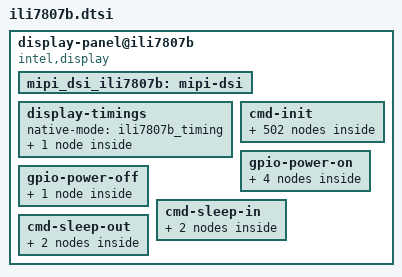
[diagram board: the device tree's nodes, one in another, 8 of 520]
/*
 * definition at "include/dt-bindings/sofiafb/sofia_fb.h"
 */

display-panel@ili7807b{
	compatible = "intel,display";
	intel,display-dc-clkrate = <297000000>;
	intel,display-preinit = <0>;
	intel,display-ramless = <1>;
	intel,display-fps = <30>;
	intel,display-vid-mode = "pulses";
	intel,display-vid-id = <0>;
	intel,display-eot = <1>;
	intel,display-gate = <1>;
	intel,display-if-dts = <1>;
	intel,display-if = <&mipi_dsi_ili7807b>;
	mipi_dsi_ili7807b:mipi-dsi {
		intel,display-if-rate = <400000000>;
		intel,display-if-nblanes = <4>;
		intel,display-if-phy-pwup = <6>;
		intel,display-if-phy-calib = <3>;
		intel,display-if-phy-to_lp_hs_req = <24>;
		intel,display-if-phy-to_lp_hs_dis = <25>;
		intel,display-if-phy-to_lp_hs_eot = <60>;
		intel,display-if-phy-to_hs_zero = <13>;
		intel,display-if-phy-to_hs_flip = <24>;
		intel,display-if-phy-lp_clk_div = <31>;
		intel,display-if-phy-to_hs_clk_pre = <36>;
		intel,display-if-phy-to_hs_clk_post = <42>;
		intel,display-if-phy-data_delay = <7>;
		intel,display-if-phy-clock_delay = <7>;
		intel,display-if-phy-lp_tx_tfall = <2>;
		intel,display-if-phy-lp_tx_rise = <2>;
		intel,display-if-phy-lp_tx_vref = <31>;
	};

	display-timings {
		native-mode = <&ili7807b_timing>;
		ili7807b_timing: ili7807b_timing {
			screen-type = <SCREEN_MIPI>;
			out-face    = <OUT_P888>;
			color-mode = <COLOR_RGB>;
			width = <75>;
			height = <132>;
			clock-frequency = <65774400>;
			hactive = <1080>;
			vactive = <1920>;
			hback-porch = <24>;
			hfront-porch = <24>;
			vback-porch = <4>;
			vfront-porch = <4>;
			hsync-len = <8>;
			vsync-len = <2>;
			hsync-active = <0>;
			vsync-active = <0>;
			de-active = <0>;
			pixelclk-active = <0>;
			swap-rb = <0>;
			swap-rg = <0>;
			swap-gb = <0>;
		};
	};

	cmd-init {
	    ili7807b_cmd0 {
		     intel,cmd-type = <0x39>;
		     intel,cmd-data = <0xFF 0x78 0x07 0x01>;
		     intel,cmd-lp = <1>;
		 };
	    ili7807b_cmd1 {
		     intel,cmd-type = <0x15>;
		     intel,cmd-data = <0x42 0x11>;
		     intel,cmd-lp = <1>;
		 };
	    ili7807b_cmd2 {
		     intel,cmd-type = <0x15>;
		     intel,cmd-data = <0x43 0xB0>;
		     intel,cmd-lp = <1>;
		 };
	    ili7807b_cmd3 {
		     intel,cmd-type = <0x15>;
		     intel,cmd-data = <0x44 0xBA>;
		     intel,cmd-lp = <1>;
		 };
	    ili7807b_cmd4 {
		     intel,cmd-type = <0x15>;
		     intel,cmd-data = <0x45 0x29>;
		     intel,cmd-lp = <1>;
		 };
	    ili7807b_cmd5 {
		     intel,cmd-type = <0x15>;
		     intel,cmd-data = <0x46 0x39>;
		     intel,cmd-lp = <1>;
		 };
	    ili7807b_cmd6 {
		     intel,cmd-type = <0x15>;
		     intel,cmd-data = <0x4A 0x12>;
		     intel,cmd-lp = <1>;
		 };
	    ili7807b_cmd7 {
		     intel,cmd-type = <0x15>;
		     intel,cmd-data = <0x4B 0x12>;
		     intel,cmd-lp = <1>;
		 };
	    ili7807b_cmd8 {
		     intel,cmd-type = <0x15>;
		     intel,cmd-data = <0x50 0x3F>;
		     intel,cmd-lp = <1>;
		 };
	    ili7807b_cmd9 {
		     intel,cmd-type = <0x15>;
		     intel,cmd-data = <0x51 0x3F>;
		     intel,cmd-lp = <1>;
		 };
	    ili7807b_cmd10 {
		     intel,cmd-type = <0x15>;
		     intel,cmd-data = <0xA2 0x01>;
		     intel,cmd-lp = <1>;
		 };
	    ili7807b_cmd11 {
		     intel,cmd-type = <0x15>;
		     intel,cmd-data = <0xA3 0x1F>;
		     intel,cmd-lp = <1>;
		 };
	    ili7807b_cmd12 {
		     intel,cmd-type = <0x15>;
		     intel,cmd-data = <0xA4 0x01>;
		     intel,cmd-lp = <1>;
		 };
	    ili7807b_cmd13 {
		     intel,cmd-type = <0x15>;
		     intel,cmd-data = <0xA5 0x19>;
		     intel,cmd-lp = <1>;
		 };
	    ili7807b_cmd14 {
		     intel,cmd-type = <0x39>;
		     intel,cmd-data = <0xFF 0x78 0x07 0x01>;
		     intel,cmd-lp = <1>;
		 };
	    ili7807b_cmd15 {
		     intel,cmd-type = <0x15>;
		     intel,cmd-data = <0x22 0x06>;
		     intel,cmd-lp = <1>;
		 };
	    ili7807b_cmd16 {
		     intel,cmd-type = <0x15>;
		     intel,cmd-data = <0x36 0x01>;
		     intel,cmd-lp = <1>;
		 };
	    ili7807b_cmd17 {
		     intel,cmd-type = <0x15>;
		     intel,cmd-data = <0x64 0x10>;
		     intel,cmd-lp = <1>;
		 };
	    ili7807b_cmd18 {
		     intel,cmd-type = <0x15>;
		     intel,cmd-data = <0x6C 0x45>;
		     intel,cmd-lp = <1>;
		 };
	    ili7807b_cmd19 {
		     intel,cmd-type = <0x15>;
		     intel,cmd-data = <0x6D 0x17>;
		     intel,cmd-lp = <1>;
		 };
	    ili7807b_cmd20 {
		     intel,cmd-type = <0x39>;
		     intel,cmd-data = <0xFF 0x78 0x07 0x06>;
		     intel,cmd-lp = <1>;
		 };
	    ili7807b_cmd21 {
		     intel,cmd-type = <0x15>;
		     intel,cmd-data = <0x00 0x41>;
		     intel,cmd-lp = <1>;
		 };
	    ili7807b_cmd22 {
		     intel,cmd-type = <0x15>;
		     intel,cmd-data = <0x01 0x01>;
		     intel,cmd-lp = <1>;
		 };
	    ili7807b_cmd23 {
		     intel,cmd-type = <0x15>;
		     intel,cmd-data = <0x02 0x22>;
		     intel,cmd-lp = <1>;
		 };
	    ili7807b_cmd24 {
		     intel,cmd-type = <0x15>;
		     intel,cmd-data = <0x03 0x22>;
		     intel,cmd-lp = <1>;
		 };
	    ili7807b_cmd25 {
		     intel,cmd-type = <0x15>;
		     intel,cmd-data = <0x04 0x02>;
		     intel,cmd-lp = <1>;
		 };
	    ili7807b_cmd26 {
		     intel,cmd-type = <0x15>;
		     intel,cmd-data = <0x05 0x00>;
		     intel,cmd-lp = <1>;
		 };
	    ili7807b_cmd27 {
		     intel,cmd-type = <0x15>;
		     intel,cmd-data = <0x06 0x04>;
		     intel,cmd-lp = <1>;
		 };
	    ili7807b_cmd28 {
		     intel,cmd-type = <0x15>;
		     intel,cmd-data = <0x07 0x00>;
		     intel,cmd-lp = <1>;
		 };
	    ili7807b_cmd29 {
		     intel,cmd-type = <0x15>;
		     intel,cmd-data = <0x08 0x00>;
		     intel,cmd-lp = <1>;
		 };
	    ili7807b_cmd30 {
		     intel,cmd-type = <0x15>;
		     intel,cmd-data = <0x09 0x00>;
		     intel,cmd-lp = <1>;
		 };
	    ili7807b_cmd31 {
		     intel,cmd-type = <0x15>;
		     intel,cmd-data = <0x0A 0x10>;
		     intel,cmd-lp = <1>;
		 };
	    ili7807b_cmd32 {
		     intel,cmd-type = <0x15>;
		     intel,cmd-data = <0x0B 0x30>;
		     intel,cmd-lp = <1>;
		 };
	    ili7807b_cmd33 {
		     intel,cmd-type = <0x15>;
		     intel,cmd-data = <0x0C 0x04>;
		     intel,cmd-lp = <1>;
		 };
	    ili7807b_cmd34 {
		     intel,cmd-type = <0x15>;
		     intel,cmd-data = <0x0D 0x04>;
		     intel,cmd-lp = <1>;
		 };
	    ili7807b_cmd35 {
		     intel,cmd-type = <0x15>;
		     intel,cmd-data = <0x0E 0x00>;
		     intel,cmd-lp = <1>;
		 };
	    ili7807b_cmd36 {
		     intel,cmd-type = <0x15>;
		     intel,cmd-data = <0x0F 0x00>;
		     intel,cmd-lp = <1>;
		 };
	    ili7807b_cmd37 {
		     intel,cmd-type = <0x15>;
		     intel,cmd-data = <0x10 0x00>;
		     intel,cmd-lp = <1>;
		 };
	    ili7807b_cmd38 {
		     intel,cmd-type = <0x15>;
		     intel,cmd-data = <0x11 0x00>;
		     intel,cmd-lp = <1>;
		 };
	    ili7807b_cmd39 {
		     intel,cmd-type = <0x15>;
		     intel,cmd-data = <0x12 0x00>;
		     intel,cmd-lp = <1>;
		 };
	    ili7807b_cmd40 {
		     intel,cmd-type = <0x15>;
		     intel,cmd-data = <0x13 0x00>;
		     intel,cmd-lp = <1>;
		 };
	    ili7807b_cmd41 {
		     intel,cmd-type = <0x15>;
		     intel,cmd-data = <0x14 0x00>;
		     intel,cmd-lp = <1>;
		 };
	    ili7807b_cmd42 {
		     intel,cmd-type = <0x15>;
		     intel,cmd-data = <0x15 0x00>;
		     intel,cmd-lp = <1>;
		 };
	    ili7807b_cmd43 {
		     intel,cmd-type = <0x15>;
		     intel,cmd-data = <0x31 0x08>;
		     intel,cmd-lp = <1>;
		 };
	    ili7807b_cmd44 {
		     intel,cmd-type = <0x15>;
		     intel,cmd-data = <0x32 0x01>;
		     intel,cmd-lp = <1>;
		 };
	    ili7807b_cmd45 {
		     intel,cmd-type = <0x15>;
		     intel,cmd-data = <0x33 0x00>;
		     intel,cmd-lp = <1>;
		 };
	    ili7807b_cmd46 {
		     intel,cmd-type = <0x15>;
		     intel,cmd-data = <0x34 0x11>;
		     intel,cmd-lp = <1>;
		 };
	    ili7807b_cmd47 {
		     intel,cmd-type = <0x15>;
		     intel,cmd-data = <0x35 0x10>;
		     intel,cmd-lp = <1>;
		 };
	    ili7807b_cmd48 {
		     intel,cmd-type = <0x15>;
		     intel,cmd-data = <0x36 0x26>;
		     intel,cmd-lp = <1>;
		 };
	    ili7807b_cmd49 {
		     intel,cmd-type = <0x15>;
		     intel,cmd-data = <0x37 0x22>;
		     intel,cmd-lp = <1>;
		 };
	    ili7807b_cmd50 {
		     intel,cmd-type = <0x15>;
		     intel,cmd-data = <0x38 0x22>;
		     intel,cmd-lp = <1>;
		 };
	    ili7807b_cmd51 {
		     intel,cmd-type = <0x15>;
		     intel,cmd-data = <0x39 0x0C>;
		     intel,cmd-lp = <1>;
		 };
	    ili7807b_cmd52 {
		     intel,cmd-type = <0x15>;
		     intel,cmd-data = <0x3A 0x02>;
		     intel,cmd-lp = <1>;
		 };
	    ili7807b_cmd53 {
		     intel,cmd-type = <0x15>;
		     intel,cmd-data = <0x3B 0x02>;
		     intel,cmd-lp = <1>;
		 };
	    ili7807b_cmd54 {
		     intel,cmd-type = <0x15>;
		     intel,cmd-data = <0x3C 0x02>;
		     intel,cmd-lp = <1>;
		 };
	    ili7807b_cmd55 {
		     intel,cmd-type = <0x15>;
		     intel,cmd-data = <0x3D 0x02>;
		     intel,cmd-lp = <1>;
		 };
	    ili7807b_cmd56 {
		     intel,cmd-type = <0x15>;
		     intel,cmd-data = <0x3E 0x28>;
		     intel,cmd-lp = <1>;
		 };
	    ili7807b_cmd57 {
		     intel,cmd-type = <0x15>;
		     intel,cmd-data = <0x3F 0x29>;
		     intel,cmd-lp = <1>;
		 };
	    ili7807b_cmd58 {
		     intel,cmd-type = <0x15>;
		     intel,cmd-data = <0x40 0x2A>;
		     intel,cmd-lp = <1>;
		 };
	    ili7807b_cmd59 {
		     intel,cmd-type = <0x15>;
		     intel,cmd-data = <0x41 0x08>;
		     intel,cmd-lp = <1>;
		 };
	    ili7807b_cmd60 {
		     intel,cmd-type = <0x15>;
		     intel,cmd-data = <0x42 0x01>;
		     intel,cmd-lp = <1>;
		 };
	    ili7807b_cmd61 {
		     intel,cmd-type = <0x15>;
		     intel,cmd-data = <0x43 0x00>;
		     intel,cmd-lp = <1>;
		 };
	    ili7807b_cmd62 {
		     intel,cmd-type = <0x15>;
		     intel,cmd-data = <0x44 0x11>;
		     intel,cmd-lp = <1>;
		 };
	    ili7807b_cmd63 {
		     intel,cmd-type = <0x15>;
		     intel,cmd-data = <0x45 0x10>;
		     intel,cmd-lp = <1>;
		 };
	    ili7807b_cmd64 {
		     intel,cmd-type = <0x15>;
		     intel,cmd-data = <0x46 0x26>;
		     intel,cmd-lp = <1>;
		 };
	    ili7807b_cmd65 {
		     intel,cmd-type = <0x15>;
		     intel,cmd-data = <0x47 0x22>;
		     intel,cmd-lp = <1>;
		 };
	    ili7807b_cmd66 {
		     intel,cmd-type = <0x15>;
		     intel,cmd-data = <0x48 0x02>;
		     intel,cmd-lp = <1>;
		 };
	    ili7807b_cmd67 {
		     intel,cmd-type = <0x15>;
		     intel,cmd-data = <0x49 0x0C>;
		     intel,cmd-lp = <1>;
		 };
	    ili7807b_cmd68 {
		     intel,cmd-type = <0x15>;
		     intel,cmd-data = <0x4A 0x02>;
		     intel,cmd-lp = <1>;
		 };
	    ili7807b_cmd69 {
		     intel,cmd-type = <0x15>;
		     intel,cmd-data = <0x4B 0x02>;
		     intel,cmd-lp = <1>;
		 };
	    ili7807b_cmd70 {
		     intel,cmd-type = <0x15>;
		     intel,cmd-data = <0x4C 0x02>;
		     intel,cmd-lp = <1>;
		 };
	    ili7807b_cmd71 {
		     intel,cmd-type = <0x15>;
		     intel,cmd-data = <0x4D 0x02>;
		     intel,cmd-lp = <1>;
		 };
	    ili7807b_cmd72 {
		     intel,cmd-type = <0x15>;
		     intel,cmd-data = <0x4E 0x28>;
		     intel,cmd-lp = <1>;
		 };
	    ili7807b_cmd73 {
		     intel,cmd-type = <0x15>;
		     intel,cmd-data = <0x4F 0x29>;
		     intel,cmd-lp = <1>;
		 };
	    ili7807b_cmd74 {
		     intel,cmd-type = <0x15>;
		     intel,cmd-data = <0x50 0x2A>;
		     intel,cmd-lp = <1>;
		 };
	    ili7807b_cmd75 {
		     intel,cmd-type = <0x15>;
		     intel,cmd-data = <0x61 0x0C>;
		     intel,cmd-lp = <1>;
		 };
	    ili7807b_cmd76 {
		     intel,cmd-type = <0x15>;
		     intel,cmd-data = <0x62 0x01>;
		     intel,cmd-lp = <1>;
		 };
	    ili7807b_cmd77 {
		     intel,cmd-type = <0x15>;
		     intel,cmd-data = <0x63 0x00>;
		     intel,cmd-lp = <1>;
		 };
	    ili7807b_cmd78 {
		     intel,cmd-type = <0x15>;
		     intel,cmd-data = <0x64 0x10>;
		     intel,cmd-lp = <1>;
		 };
	    ili7807b_cmd79 {
		     intel,cmd-type = <0x15>;
		     intel,cmd-data = <0x65 0x11>;
		     intel,cmd-lp = <1>;
		 };
	    ili7807b_cmd80 {
		     intel,cmd-type = <0x15>;
		     intel,cmd-data = <0x66 0x26>;
		     intel,cmd-lp = <1>;
		 };
	    ili7807b_cmd81 {
		     intel,cmd-type = <0x15>;
		     intel,cmd-data = <0x67 0x22>;
		     intel,cmd-lp = <1>;
		 };
	    ili7807b_cmd82 {
		     intel,cmd-type = <0x15>;
		     intel,cmd-data = <0x68 0x22>;
		     intel,cmd-lp = <1>;
		 };
	    ili7807b_cmd83 {
		     intel,cmd-type = <0x15>;
		     intel,cmd-data = <0x69 0x08>;
		     intel,cmd-lp = <1>;
		 };
	    ili7807b_cmd84 {
		     intel,cmd-type = <0x15>;
		     intel,cmd-data = <0x6A 0x02>;
		     intel,cmd-lp = <1>;
		 };
	    ili7807b_cmd85 {
		     intel,cmd-type = <0x15>;
		     intel,cmd-data = <0x6B 0x02>;
		     intel,cmd-lp = <1>;
		 };
	    ili7807b_cmd86 {
		     intel,cmd-type = <0x15>;
		     intel,cmd-data = <0x6C 0x02>;
		     intel,cmd-lp = <1>;
		 };
	    ili7807b_cmd87 {
		     intel,cmd-type = <0x15>;
		     intel,cmd-data = <0x6D 0x02>;
		     intel,cmd-lp = <1>;
		 };
	    ili7807b_cmd88 {
		     intel,cmd-type = <0x15>;
		     intel,cmd-data = <0x6E 0x28>;
		     intel,cmd-lp = <1>;
		 };
	    ili7807b_cmd89 {
		     intel,cmd-type = <0x15>;
		     intel,cmd-data = <0x6F 0x29>;
		     intel,cmd-lp = <1>;
		 };
	    ili7807b_cmd90 {
		     intel,cmd-type = <0x15>;
		     intel,cmd-data = <0x70 0x2A>;
		     intel,cmd-lp = <1>;
		 };
	    ili7807b_cmd91 {
		     intel,cmd-type = <0x15>;
		     intel,cmd-data = <0x71 0x0C>;
		     intel,cmd-lp = <1>;
		 };
	    ili7807b_cmd92 {
		     intel,cmd-type = <0x15>;
		     intel,cmd-data = <0x72 0x01>;
		     intel,cmd-lp = <1>;
		 };
	    ili7807b_cmd93 {
		     intel,cmd-type = <0x15>;
		     intel,cmd-data = <0x73 0x00>;
		     intel,cmd-lp = <1>;
		 };
	    ili7807b_cmd94 {
		     intel,cmd-type = <0x15>;
		     intel,cmd-data = <0x74 0x10>;
		     intel,cmd-lp = <1>;
		 };
	    ili7807b_cmd95 {
		     intel,cmd-type = <0x15>;
		     intel,cmd-data = <0x75 0x11>;
		     intel,cmd-lp = <1>;
		 };
	    ili7807b_cmd96 {
		     intel,cmd-type = <0x15>;
		     intel,cmd-data = <0x76 0x26>;
		     intel,cmd-lp = <1>;
		 };
	    ili7807b_cmd97 {
		     intel,cmd-type = <0x15>;
		     intel,cmd-data = <0x77 0x22>;
		     intel,cmd-lp = <1>;
		 };
	    ili7807b_cmd98 {
		     intel,cmd-type = <0x15>;
		     intel,cmd-data = <0x78 0x02>;
		     intel,cmd-lp = <1>;
		 };
	    ili7807b_cmd99 {
		     intel,cmd-type = <0x15>;
		     intel,cmd-data = <0x79 0x08>;
		     intel,cmd-lp = <1>;
		 };
	    ili7807b_cmd100 {
		     intel,cmd-type = <0x15>;
		     intel,cmd-data = <0x7A 0x02>;
		     intel,cmd-lp = <1>;
		 };
	    ili7807b_cmd101 {
		     intel,cmd-type = <0x15>;
		     intel,cmd-data = <0x7B 0x02>;
		     intel,cmd-lp = <1>;
		 };
	    ili7807b_cmd102 {
		     intel,cmd-type = <0x15>;
		     intel,cmd-data = <0x7C 0x02>;
		     intel,cmd-lp = <1>;
		 };
	    ili7807b_cmd103 {
		     intel,cmd-type = <0x15>;
		     intel,cmd-data = <0x7D 0x02>;
		     intel,cmd-lp = <1>;
		 };
	    ili7807b_cmd104 {
		     intel,cmd-type = <0x15>;
		     intel,cmd-data = <0x7E 0x28>;
		     intel,cmd-lp = <1>;
		 };
	    ili7807b_cmd105 {
		     intel,cmd-type = <0x15>;
		     intel,cmd-data = <0x7F 0x29>;
		     intel,cmd-lp = <1>;
		 };
	    ili7807b_cmd106 {
		     intel,cmd-type = <0x15>;
		     intel,cmd-data = <0x80 0x2A>;
		     intel,cmd-lp = <1>;
		 };
	    ili7807b_cmd107 {
		     intel,cmd-type = <0x15>;
		     intel,cmd-data = <0xD0 0x01>;
		     intel,cmd-lp = <1>;
		 };
	    ili7807b_cmd108 {
		     intel,cmd-type = <0x15>;
		     intel,cmd-data = <0xD1 0x01>;
		     intel,cmd-lp = <1>;
		 };
	    ili7807b_cmd109 {
		     intel,cmd-type = <0x15>;
		     intel,cmd-data = <0xD2 0x10>;
		     intel,cmd-lp = <1>;
		 };
	    ili7807b_cmd110 {
		     intel,cmd-type = <0x15>;
		     intel,cmd-data = <0xD3 0x00>;
		     intel,cmd-lp = <1>;
		 };
	    ili7807b_cmd111 {
		     intel,cmd-type = <0x15>;
		     intel,cmd-data = <0xD4 0x00>;
		     intel,cmd-lp = <1>;
		 };
	    ili7807b_cmd112 {
		     intel,cmd-type = <0x15>;
		     intel,cmd-data = <0xD5 0x00>;
		     intel,cmd-lp = <1>;
		 };
	    ili7807b_cmd113 {
		     intel,cmd-type = <0x15>;
		     intel,cmd-data = <0xD6 0x00>;
		     intel,cmd-lp = <1>;
		 };
	    ili7807b_cmd114 {
		     intel,cmd-type = <0x15>;
		     intel,cmd-data = <0xD7 0x00>;
		     intel,cmd-lp = <1>;
		 };
	    ili7807b_cmd115 {
		     intel,cmd-type = <0x15>;
		     intel,cmd-data = <0xD8 0x00>;
		     intel,cmd-lp = <1>;
		 };
	    ili7807b_cmd116 {
		     intel,cmd-type = <0x15>;
		     intel,cmd-data = <0xD9 0x00>;
		     intel,cmd-lp = <1>;
		 };
	    ili7807b_cmd117 {
		     intel,cmd-type = <0x15>;
		     intel,cmd-data = <0xDA 0x00>;
		     intel,cmd-lp = <1>;
		 };
	    ili7807b_cmd118 {
		     intel,cmd-type = <0x15>;
		     intel,cmd-data = <0xDB 0x47>;
		     intel,cmd-lp = <1>;
		 };
	    ili7807b_cmd119 {
		     intel,cmd-type = <0x15>;
		     intel,cmd-data = <0xDC 0x06>;
		     intel,cmd-lp = <1>;
		 };
	    ili7807b_cmd120 {
		     intel,cmd-type = <0x15>;
		     intel,cmd-data = <0xDD 0x55>;
		     intel,cmd-lp = <1>;
		 };
	    ili7807b_cmd121 {
		     intel,cmd-type = <0x15>;
		     intel,cmd-data = <0x96 0x00>;
		     intel,cmd-lp = <1>;
		 };
	    ili7807b_cmd122 {
		     intel,cmd-type = <0x15>;
		     intel,cmd-data = <0x97 0x12>;
		     intel,cmd-lp = <1>;
		 };
	    ili7807b_cmd123 {
		     intel,cmd-type = <0x15>;
		     intel,cmd-data = <0xA0 0x08>;
		     intel,cmd-lp = <1>;
		 };
	    ili7807b_cmd124 {
		     intel,cmd-type = <0x15>;
		     intel,cmd-data = <0xA1 0x00>;
		     intel,cmd-lp = <1>;
		 };
	    ili7807b_cmd125 {
		     intel,cmd-type = <0x15>;
		     intel,cmd-data = <0xA2 0x04>;
		     intel,cmd-lp = <1>;
		 };
	    ili7807b_cmd126 {
		     intel,cmd-type = <0x15>;
		     intel,cmd-data = <0xA3 0x0F>;
		     intel,cmd-lp = <1>;
		 };
	    ili7807b_cmd127 {
		     intel,cmd-type = <0x15>;
		     intel,cmd-data = <0xA7 0x00>;
		     intel,cmd-lp = <1>;
		 };
	    ili7807b_cmd128 {
		     intel,cmd-type = <0x15>;
		     intel,cmd-data = <0xE5 0x80>;
		     intel,cmd-lp = <1>;
		 };
	    ili7807b_cmd129 {
		     intel,cmd-type = <0x39>;
		     intel,cmd-data = <0xFF 0x78 0x07 0x02>;
		     intel,cmd-lp = <1>;
		 };
	    ili7807b_cmd130 {
		     intel,cmd-type = <0x15>;
		     intel,cmd-data = <0x00 0x00>;
		     intel,cmd-lp = <1>;
		 };
	    ili7807b_cmd131 {
		     intel,cmd-type = <0x15>;
		     intel,cmd-data = <0x01 0x00>;
		     intel,cmd-lp = <1>;
		 };
	    ili7807b_cmd132 {
		     intel,cmd-type = <0x15>;
		     intel,cmd-data = <0x02 0x00>;
		     intel,cmd-lp = <1>;
		 };
	    ili7807b_cmd133 {
		     intel,cmd-type = <0x15>;
		     intel,cmd-data = <0x03 0x19>;
		     intel,cmd-lp = <1>;
		 };
	    ili7807b_cmd134 {
		     intel,cmd-type = <0x15>;
		     intel,cmd-data = <0x04 0x00>;
		     intel,cmd-lp = <1>;
		 };
	    ili7807b_cmd135 {
		     intel,cmd-type = <0x15>;
		     intel,cmd-data = <0x05 0x48>;
		     intel,cmd-lp = <1>;
		 };
	    ili7807b_cmd136 {
		     intel,cmd-type = <0x15>;
		     intel,cmd-data = <0x06 0x00>;
		     intel,cmd-lp = <1>;
		 };
	    ili7807b_cmd137 {
		     intel,cmd-type = <0x15>;
		     intel,cmd-data = <0x07 0x66>;
		     intel,cmd-lp = <1>;
		 };
	    ili7807b_cmd138 {
		     intel,cmd-type = <0x15>;
		     intel,cmd-data = <0x08 0x00>;
		     intel,cmd-lp = <1>;
		 };
	    ili7807b_cmd139 {
		     intel,cmd-type = <0x15>;
		     intel,cmd-data = <0x09 0x7F>;
		     intel,cmd-lp = <1>;
		 };
	    ili7807b_cmd140 {
		     intel,cmd-type = <0x15>;
		     intel,cmd-data = <0x0A 0x00>;
		     intel,cmd-lp = <1>;
		 };
	    ili7807b_cmd141 {
		     intel,cmd-type = <0x15>;
		     intel,cmd-data = <0x0B 0x94>;
		     intel,cmd-lp = <1>;
		 };
	    ili7807b_cmd142 {
		     intel,cmd-type = <0x15>;
		     intel,cmd-data = <0x0C 0x00>;
		     intel,cmd-lp = <1>;
		 };
	    ili7807b_cmd143 {
		     intel,cmd-type = <0x15>;
		     intel,cmd-data = <0x0D 0xA6>;
		     intel,cmd-lp = <1>;
		 };
	    ili7807b_cmd144 {
		     intel,cmd-type = <0x15>;
		     intel,cmd-data = <0x0E 0x00>;
		     intel,cmd-lp = <1>;
		 };
	    ili7807b_cmd145 {
		     intel,cmd-type = <0x15>;
		     intel,cmd-data = <0x0F 0xB5>;
		     intel,cmd-lp = <1>;
		 };
	    ili7807b_cmd146 {
		     intel,cmd-type = <0x15>;
		     intel,cmd-data = <0x10 0x00>;
		     intel,cmd-lp = <1>;
		 };
	    ili7807b_cmd147 {
		     intel,cmd-type = <0x15>;
		     intel,cmd-data = <0x11 0xC4>;
		     intel,cmd-lp = <1>;
		 };
	    ili7807b_cmd148 {
		     intel,cmd-type = <0x15>;
		     intel,cmd-data = <0x12 0x00>;
		     intel,cmd-lp = <1>;
		 };
	    ili7807b_cmd149 {
		     intel,cmd-type = <0x15>;
		     intel,cmd-data = <0x13 0xF6>;
		     intel,cmd-lp = <1>;
		 };
	    ili7807b_cmd150 {
		     intel,cmd-type = <0x15>;
		     intel,cmd-data = <0x14 0x01>;
		     intel,cmd-lp = <1>;
		 };
	    ili7807b_cmd151 {
		     intel,cmd-type = <0x15>;
		     intel,cmd-data = <0x15 0x1E>;
		     intel,cmd-lp = <1>;
		 };
	    ili7807b_cmd152 {
		     intel,cmd-type = <0x15>;
		     intel,cmd-data = <0x16 0x01>;
		     intel,cmd-lp = <1>;
		 };
	    ili7807b_cmd153 {
		     intel,cmd-type = <0x15>;
		     intel,cmd-data = <0x17 0x5D>;
		     intel,cmd-lp = <1>;
		 };
	    ili7807b_cmd154 {
		     intel,cmd-type = <0x15>;
		     intel,cmd-data = <0x18 0x01>;
		     intel,cmd-lp = <1>;
		 };
	    ili7807b_cmd155 {
		     intel,cmd-type = <0x15>;
		     intel,cmd-data = <0x19 0x8E>;
		     intel,cmd-lp = <1>;
		 };
	    ili7807b_cmd156 {
		     intel,cmd-type = <0x15>;
		     intel,cmd-data = <0x1A 0x01>;
		     intel,cmd-lp = <1>;
		 };
	    ili7807b_cmd157 {
		     intel,cmd-type = <0x15>;
		     intel,cmd-data = <0x1B 0xDA>;
		     intel,cmd-lp = <1>;
		 };
	    ili7807b_cmd158 {
		     intel,cmd-type = <0x15>;
		     intel,cmd-data = <0x1C 0x02>;
		     intel,cmd-lp = <1>;
		 };
	    ili7807b_cmd159 {
		     intel,cmd-type = <0x15>;
		     intel,cmd-data = <0x1D 0x16>;
		     intel,cmd-lp = <1>;
		 };
	    ili7807b_cmd160 {
		     intel,cmd-type = <0x15>;
		     intel,cmd-data = <0x1E 0x02>;
		     intel,cmd-lp = <1>;
		 };
	    ili7807b_cmd161 {
		     intel,cmd-type = <0x15>;
		     intel,cmd-data = <0x1F 0x18>;
		     intel,cmd-lp = <1>;
		 };
	    ili7807b_cmd162 {
		     intel,cmd-type = <0x15>;
		     intel,cmd-data = <0x20 0x02>;
		     intel,cmd-lp = <1>;
		 };
	    ili7807b_cmd163 {
		     intel,cmd-type = <0x15>;
		     intel,cmd-data = <0x21 0x4D>;
		     intel,cmd-lp = <1>;
		 };
	    ili7807b_cmd164 {
		     intel,cmd-type = <0x15>;
		     intel,cmd-data = <0x22 0x02>;
		     intel,cmd-lp = <1>;
		 };
	    ili7807b_cmd165 {
		     intel,cmd-type = <0x15>;
		     intel,cmd-data = <0x23 0x87>;
		     intel,cmd-lp = <1>;
		 };
	    ili7807b_cmd166 {
		     intel,cmd-type = <0x15>;
		     intel,cmd-data = <0x24 0x02>;
		     intel,cmd-lp = <1>;
		 };
	    ili7807b_cmd167 {
		     intel,cmd-type = <0x15>;
		     intel,cmd-data = <0x25 0xAC>;
		     intel,cmd-lp = <1>;
		 };
	    ili7807b_cmd168 {
		     intel,cmd-type = <0x15>;
		     intel,cmd-data = <0x26 0x02>;
		     intel,cmd-lp = <1>;
		 };
	    ili7807b_cmd169 {
		     intel,cmd-type = <0x15>;
		     intel,cmd-data = <0x27 0xDE>;
		     intel,cmd-lp = <1>;
		 };
	    ili7807b_cmd170 {
		     intel,cmd-type = <0x15>;
		     intel,cmd-data = <0x28 0x03>;
		     intel,cmd-lp = <1>;
		 };
	    ili7807b_cmd171 {
		     intel,cmd-type = <0x15>;
		     intel,cmd-data = <0x29 0x01>;
		     intel,cmd-lp = <1>;
		 };
	    ili7807b_cmd172 {
		     intel,cmd-type = <0x15>;
		     intel,cmd-data = <0x2A 0x03>;
		     intel,cmd-lp = <1>;
		 };
	    ili7807b_cmd173 {
		     intel,cmd-type = <0x15>;
		     intel,cmd-data = <0x2B 0x2D>;
		     intel,cmd-lp = <1>;
		 };
	    ili7807b_cmd174 {
		     intel,cmd-type = <0x15>;
		     intel,cmd-data = <0x2C 0x03>;
		     intel,cmd-lp = <1>;
		 };
	    ili7807b_cmd175 {
		     intel,cmd-type = <0x15>;
		     intel,cmd-data = <0x2D 0x3B>;
		     intel,cmd-lp = <1>;
		 };
	    ili7807b_cmd176 {
		     intel,cmd-type = <0x15>;
		     intel,cmd-data = <0x2E 0x03>;
		     intel,cmd-lp = <1>;
		 };
	    ili7807b_cmd177 {
		     intel,cmd-type = <0x15>;
		     intel,cmd-data = <0x2F 0x4A>;
		     intel,cmd-lp = <1>;
		 };
	    ili7807b_cmd178 {
		     intel,cmd-type = <0x15>;
		     intel,cmd-data = <0x30 0x03>;
		     intel,cmd-lp = <1>;
		 };
	    ili7807b_cmd179 {
		     intel,cmd-type = <0x15>;
		     intel,cmd-data = <0x31 0x5A>;
		     intel,cmd-lp = <1>;
		 };
	    ili7807b_cmd180 {
		     intel,cmd-type = <0x15>;
		     intel,cmd-data = <0x32 0x03>;
		     intel,cmd-lp = <1>;
		 };
	    ili7807b_cmd181 {
		     intel,cmd-type = <0x15>;
		     intel,cmd-data = <0x33 0x6D>;
		     intel,cmd-lp = <1>;
		 };
	    ili7807b_cmd182 {
		     intel,cmd-type = <0x15>;
		     intel,cmd-data = <0x34 0x03>;
		     intel,cmd-lp = <1>;
		 };
	    ili7807b_cmd183 {
		     intel,cmd-type = <0x15>;
		     intel,cmd-data = <0x35 0x82>;
		     intel,cmd-lp = <1>;
		 };
	    ili7807b_cmd184 {
		     intel,cmd-type = <0x15>;
		     intel,cmd-data = <0x36 0x03>;
		     intel,cmd-lp = <1>;
		 };
	    ili7807b_cmd185 {
		     intel,cmd-type = <0x15>;
		     intel,cmd-data = <0x37 0x9A>;
		     intel,cmd-lp = <1>;
		 };
	    ili7807b_cmd186 {
		     intel,cmd-type = <0x15>;
		     intel,cmd-data = <0x38 0x03>;
		     intel,cmd-lp = <1>;
		 };
	    ili7807b_cmd187 {
		     intel,cmd-type = <0x15>;
		     intel,cmd-data = <0x39 0xB3>;
		     intel,cmd-lp = <1>;
		 };
	    ili7807b_cmd188 {
		     intel,cmd-type = <0x15>;
		     intel,cmd-data = <0x3A 0x03>;
		     intel,cmd-lp = <1>;
		 };
	    ili7807b_cmd189 {
		     intel,cmd-type = <0x15>;
		     intel,cmd-data = <0x3B 0xCE>;
		     intel,cmd-lp = <1>;
		 };
	    ili7807b_cmd190 {
		     intel,cmd-type = <0x15>;
		     intel,cmd-data = <0x3C 0x00>;
		     intel,cmd-lp = <1>;
		 };
	    ili7807b_cmd191 {
		     intel,cmd-type = <0x15>;
		     intel,cmd-data = <0x3D 0x00>;
		     intel,cmd-lp = <1>;
		 };
	    ili7807b_cmd192 {
		     intel,cmd-type = <0x15>;
		     intel,cmd-data = <0x3E 0x00>;
		     intel,cmd-lp = <1>;
		 };
	    ili7807b_cmd193 {
		     intel,cmd-type = <0x15>;
		     intel,cmd-data = <0x3F 0x19>;
		     intel,cmd-lp = <1>;
		 };
	    ili7807b_cmd194 {
		     intel,cmd-type = <0x15>;
		     intel,cmd-data = <0x40 0x00>;
		     intel,cmd-lp = <1>;
		 };
	    ili7807b_cmd195 {
		     intel,cmd-type = <0x15>;
		     intel,cmd-data = <0x41 0x48>;
		     intel,cmd-lp = <1>;
		 };
	    ili7807b_cmd196 {
		     intel,cmd-type = <0x15>;
		     intel,cmd-data = <0x42 0x00>;
		     intel,cmd-lp = <1>;
		 };
	    ili7807b_cmd197 {
		     intel,cmd-type = <0x15>;
		     intel,cmd-data = <0x43 0x66>;
		     intel,cmd-lp = <1>;
		 };
	    ili7807b_cmd198 {
		     intel,cmd-type = <0x15>;
		     intel,cmd-data = <0x44 0x00>;
		     intel,cmd-lp = <1>;
		 };
	    ili7807b_cmd199 {
		     intel,cmd-type = <0x15>;
		     intel,cmd-data = <0x45 0x7F>;
		     intel,cmd-lp = <1>;
		 };
	    ili7807b_cmd200 {
		     intel,cmd-type = <0x15>;
		     intel,cmd-data = <0x46 0x00>;
		     intel,cmd-lp = <1>;
		 };
	    ili7807b_cmd201 {
		     intel,cmd-type = <0x15>;
		     intel,cmd-data = <0x47 0x94>;
		     intel,cmd-lp = <1>;
		 };
	    ili7807b_cmd202 {
		     intel,cmd-type = <0x15>;
		     intel,cmd-data = <0x48 0x00>;
		     intel,cmd-lp = <1>;
		 };
	    ili7807b_cmd203 {
		     intel,cmd-type = <0x15>;
		     intel,cmd-data = <0x49 0xA6>;
		     intel,cmd-lp = <1>;
		 };
	    ili7807b_cmd204 {
		     intel,cmd-type = <0x15>;
		     intel,cmd-data = <0x4A 0x00>;
		     intel,cmd-lp = <1>;
		 };
	    ili7807b_cmd205 {
		     intel,cmd-type = <0x15>;
		     intel,cmd-data = <0x4B 0xB5>;
		     intel,cmd-lp = <1>;
		 };
	    ili7807b_cmd206 {
		     intel,cmd-type = <0x15>;
		     intel,cmd-data = <0x4C 0x00>;
		     intel,cmd-lp = <1>;
		 };
	    ili7807b_cmd207 {
		     intel,cmd-type = <0x15>;
		     intel,cmd-data = <0x4D 0xC4>;
		     intel,cmd-lp = <1>;
		 };
	    ili7807b_cmd208 {
		     intel,cmd-type = <0x15>;
		     intel,cmd-data = <0x4E 0x00>;
		     intel,cmd-lp = <1>;
		 };
	    ili7807b_cmd209 {
		     intel,cmd-type = <0x15>;
		     intel,cmd-data = <0x4F 0xF6>;
		     intel,cmd-lp = <1>;
		 };
	    ili7807b_cmd210 {
		     intel,cmd-type = <0x15>;
		     intel,cmd-data = <0x50 0x01>;
		     intel,cmd-lp = <1>;
		 };
	    ili7807b_cmd211 {
		     intel,cmd-type = <0x15>;
		     intel,cmd-data = <0x51 0x1E>;
		     intel,cmd-lp = <1>;
		 };
	    ili7807b_cmd212 {
		     intel,cmd-type = <0x15>;
		     intel,cmd-data = <0x52 0x01>;
		     intel,cmd-lp = <1>;
		 };
	    ili7807b_cmd213 {
		     intel,cmd-type = <0x15>;
		     intel,cmd-data = <0x53 0x5D>;
		     intel,cmd-lp = <1>;
		 };
	    ili7807b_cmd214 {
		     intel,cmd-type = <0x15>;
		     intel,cmd-data = <0x54 0x01>;
		     intel,cmd-lp = <1>;
		 };
	    ili7807b_cmd215 {
		     intel,cmd-type = <0x15>;
		     intel,cmd-data = <0x55 0x8E>;
		     intel,cmd-lp = <1>;
		 };
	    ili7807b_cmd216 {
		     intel,cmd-type = <0x15>;
		     intel,cmd-data = <0x56 0x01>;
		     intel,cmd-lp = <1>;
		 };
	    ili7807b_cmd217 {
		     intel,cmd-type = <0x15>;
		     intel,cmd-data = <0x57 0xDA>;
		     intel,cmd-lp = <1>;
		 };
	    ili7807b_cmd218 {
		     intel,cmd-type = <0x15>;
		     intel,cmd-data = <0x58 0x02>;
		     intel,cmd-lp = <1>;
		 };
	    ili7807b_cmd219 {
		     intel,cmd-type = <0x15>;
		     intel,cmd-data = <0x59 0x16>;
		     intel,cmd-lp = <1>;
		 };
	    ili7807b_cmd220 {
		     intel,cmd-type = <0x15>;
		     intel,cmd-data = <0x5A 0x02>;
		     intel,cmd-lp = <1>;
		 };
	    ili7807b_cmd221 {
		     intel,cmd-type = <0x15>;
		     intel,cmd-data = <0x5B 0x18>;
		     intel,cmd-lp = <1>;
		 };
	    ili7807b_cmd222 {
		     intel,cmd-type = <0x15>;
		     intel,cmd-data = <0x5C 0x02>;
		     intel,cmd-lp = <1>;
		 };
	    ili7807b_cmd223 {
		     intel,cmd-type = <0x15>;
		     intel,cmd-data = <0x5D 0x4D>;
		     intel,cmd-lp = <1>;
		 };
	    ili7807b_cmd224 {
		     intel,cmd-type = <0x15>;
		     intel,cmd-data = <0x5E 0x02>;
		     intel,cmd-lp = <1>;
		 };
	    ili7807b_cmd225 {
		     intel,cmd-type = <0x15>;
		     intel,cmd-data = <0x5F 0x87>;
		     intel,cmd-lp = <1>;
		 };
	    ili7807b_cmd226 {
		     intel,cmd-type = <0x15>;
		     intel,cmd-data = <0x60 0x02>;
		     intel,cmd-lp = <1>;
		 };
	    ili7807b_cmd227 {
		     intel,cmd-type = <0x15>;
		     intel,cmd-data = <0x61 0xAC>;
		     intel,cmd-lp = <1>;
		 };
	    ili7807b_cmd228 {
		     intel,cmd-type = <0x15>;
		     intel,cmd-data = <0x62 0x02>;
		     intel,cmd-lp = <1>;
		 };
	    ili7807b_cmd229 {
		     intel,cmd-type = <0x15>;
		     intel,cmd-data = <0x63 0xDE>;
		     intel,cmd-lp = <1>;
		 };
	    ili7807b_cmd230 {
		     intel,cmd-type = <0x15>;
		     intel,cmd-data = <0x64 0x03>;
		     intel,cmd-lp = <1>;
		 };
	    ili7807b_cmd231 {
		     intel,cmd-type = <0x15>;
		     intel,cmd-data = <0x65 0x01>;
		     intel,cmd-lp = <1>;
		 };
	    ili7807b_cmd232 {
		     intel,cmd-type = <0x15>;
		     intel,cmd-data = <0x66 0x03>;
		     intel,cmd-lp = <1>;
		 };
	    ili7807b_cmd233 {
		     intel,cmd-type = <0x15>;
		     intel,cmd-data = <0x67 0x2D>;
		     intel,cmd-lp = <1>;
		 };
	    ili7807b_cmd234 {
		     intel,cmd-type = <0x15>;
		     intel,cmd-data = <0x68 0x03>;
		     intel,cmd-lp = <1>;
		 };
	    ili7807b_cmd235 {
		     intel,cmd-type = <0x15>;
		     intel,cmd-data = <0x69 0x3B>;
		     intel,cmd-lp = <1>;
		 };
	    ili7807b_cmd236 {
		     intel,cmd-type = <0x15>;
		     intel,cmd-data = <0x6A 0x03>;
		     intel,cmd-lp = <1>;
		 };
	    ili7807b_cmd237 {
		     intel,cmd-type = <0x15>;
		     intel,cmd-data = <0x6B 0x4A>;
		     intel,cmd-lp = <1>;
		 };
	    ili7807b_cmd238 {
		     intel,cmd-type = <0x15>;
		     intel,cmd-data = <0x6C 0x03>;
		     intel,cmd-lp = <1>;
		 };
	    ili7807b_cmd239 {
		     intel,cmd-type = <0x15>;
		     intel,cmd-data = <0x6D 0x5A>;
		     intel,cmd-lp = <1>;
		 };
	    ili7807b_cmd240 {
		     intel,cmd-type = <0x15>;
		     intel,cmd-data = <0x6E 0x03>;
		     intel,cmd-lp = <1>;
		 };
	    ili7807b_cmd241 {
		     intel,cmd-type = <0x15>;
		     intel,cmd-data = <0x6F 0x6D>;
		     intel,cmd-lp = <1>;
		 };
	    ili7807b_cmd242 {
		     intel,cmd-type = <0x15>;
		     intel,cmd-data = <0x70 0x03>;
		     intel,cmd-lp = <1>;
		 };
	    ili7807b_cmd243 {
		     intel,cmd-type = <0x15>;
		     intel,cmd-data = <0x71 0x82>;
		     intel,cmd-lp = <1>;
		 };
	    ili7807b_cmd244 {
		     intel,cmd-type = <0x15>;
		     intel,cmd-data = <0x72 0x03>;
		     intel,cmd-lp = <1>;
		 };
	    ili7807b_cmd245 {
		     intel,cmd-type = <0x15>;
		     intel,cmd-data = <0x73 0x9A>;
		     intel,cmd-lp = <1>;
		 };
	    ili7807b_cmd246 {
		     intel,cmd-type = <0x15>;
		     intel,cmd-data = <0x74 0x03>;
		     intel,cmd-lp = <1>;
		 };
	    ili7807b_cmd247 {
		     intel,cmd-type = <0x15>;
		     intel,cmd-data = <0x75 0xB3>;
		     intel,cmd-lp = <1>;
		 };
	    ili7807b_cmd248 {
		     intel,cmd-type = <0x15>;
		     intel,cmd-data = <0x76 0x03>;
		     intel,cmd-lp = <1>;
		 };
	    ili7807b_cmd249 {
		     intel,cmd-type = <0x15>;
		     intel,cmd-data = <0x77 0xCE>;
		     intel,cmd-lp = <1>;
		 };
	    ili7807b_cmd250 {
		     intel,cmd-type = <0x15>;
		     intel,cmd-data = <0x78 0x01>;
		     intel,cmd-lp = <1>;
		 };
	    ili7807b_cmd251 {
		     intel,cmd-type = <0x15>;
		     intel,cmd-data = <0x79 0x01>;
		     intel,cmd-lp = <1>;
		 };
	    ili7807b_cmd252 {
		     intel,cmd-type = <0x39>;
		     intel,cmd-data = <0xFF 0x78 0x07 0x03>;
		     intel,cmd-lp = <1>;
		 };
	    ili7807b_cmd253 {
		     intel,cmd-type = <0x15>;
		     intel,cmd-data = <0x00 0x00>;
		     intel,cmd-lp = <1>;
		 };
	    ili7807b_cmd254 {
		     intel,cmd-type = <0x15>;
		     intel,cmd-data = <0x01 0x29>;
		     intel,cmd-lp = <1>;
		 };
	    ili7807b_cmd255 {
		     intel,cmd-type = <0x15>;
		     intel,cmd-data = <0x02 0x00>;
		     intel,cmd-lp = <1>;
		 };
	    ili7807b_cmd256 {
		     intel,cmd-type = <0x15>;
		     intel,cmd-data = <0x03 0x2A>;
		     intel,cmd-lp = <1>;
		 };
	    ili7807b_cmd257 {
		     intel,cmd-type = <0x15>;
		     intel,cmd-data = <0x04 0x00>;
		     intel,cmd-lp = <1>;
		 };
	    ili7807b_cmd258 {
		     intel,cmd-type = <0x15>;
		     intel,cmd-data = <0x05 0x4B>;
		     intel,cmd-lp = <1>;
		 };
	    ili7807b_cmd259 {
		     intel,cmd-type = <0x15>;
		     intel,cmd-data = <0x06 0x00>;
		     intel,cmd-lp = <1>;
		 };
	    ili7807b_cmd260 {
		     intel,cmd-type = <0x15>;
		     intel,cmd-data = <0x07 0x63>;
		     intel,cmd-lp = <1>;
		 };
	    ili7807b_cmd261 {
		     intel,cmd-type = <0x15>;
		     intel,cmd-data = <0x08 0x00>;
		     intel,cmd-lp = <1>;
		 };
	    ili7807b_cmd262 {
		     intel,cmd-type = <0x15>;
		     intel,cmd-data = <0x09 0x79>;
		     intel,cmd-lp = <1>;
		 };
	    ili7807b_cmd263 {
		     intel,cmd-type = <0x15>;
		     intel,cmd-data = <0x0A 0x00>;
		     intel,cmd-lp = <1>;
		 };
	    ili7807b_cmd264 {
		     intel,cmd-type = <0x15>;
		     intel,cmd-data = <0x0B 0x8D>;
		     intel,cmd-lp = <1>;
		 };
	    ili7807b_cmd265 {
		     intel,cmd-type = <0x15>;
		     intel,cmd-data = <0x0C 0x00>;
		     intel,cmd-lp = <1>;
		 };
	    ili7807b_cmd266 {
		     intel,cmd-type = <0x15>;
		     intel,cmd-data = <0x0D 0x9E>;
		     intel,cmd-lp = <1>;
		 };
	    ili7807b_cmd267 {
		     intel,cmd-type = <0x15>;
		     intel,cmd-data = <0x0E 0x00>;
		     intel,cmd-lp = <1>;
		 };
	    ili7807b_cmd268 {
		     intel,cmd-type = <0x15>;
		     intel,cmd-data = <0x0F 0xAD>;
		     intel,cmd-lp = <1>;
		 };
	    ili7807b_cmd269 {
		     intel,cmd-type = <0x15>;
		     intel,cmd-data = <0x10 0x00>;
		     intel,cmd-lp = <1>;
		 };
	    ili7807b_cmd270 {
		     intel,cmd-type = <0x15>;
		     intel,cmd-data = <0x11 0xBB>;
		     intel,cmd-lp = <1>;
		 };
	    ili7807b_cmd271 {
		     intel,cmd-type = <0x15>;
		     intel,cmd-data = <0x12 0x00>;
		     intel,cmd-lp = <1>;
		 };
	    ili7807b_cmd272 {
		     intel,cmd-type = <0x15>;
		     intel,cmd-data = <0x13 0xEC>;
		     intel,cmd-lp = <1>;
		 };
	    ili7807b_cmd273 {
		     intel,cmd-type = <0x15>;
		     intel,cmd-data = <0x14 0x01>;
		     intel,cmd-lp = <1>;
		 };
	    ili7807b_cmd274 {
		     intel,cmd-type = <0x15>;
		     intel,cmd-data = <0x15 0x14>;
		     intel,cmd-lp = <1>;
		 };
	    ili7807b_cmd275 {
		     intel,cmd-type = <0x15>;
		     intel,cmd-data = <0x16 0x01>;
		     intel,cmd-lp = <1>;
		 };
	    ili7807b_cmd276 {
		     intel,cmd-type = <0x15>;
		     intel,cmd-data = <0x17 0x54>;
		     intel,cmd-lp = <1>;
		 };
	    ili7807b_cmd277 {
		     intel,cmd-type = <0x15>;
		     intel,cmd-data = <0x18 0x01>;
		     intel,cmd-lp = <1>;
		 };
	    ili7807b_cmd278 {
		     intel,cmd-type = <0x15>;
		     intel,cmd-data = <0x19 0x86>;
		     intel,cmd-lp = <1>;
		 };
	    ili7807b_cmd279 {
		     intel,cmd-type = <0x15>;
		     intel,cmd-data = <0x1A 0x01>;
		     intel,cmd-lp = <1>;
		 };
	    ili7807b_cmd280 {
		     intel,cmd-type = <0x15>;
		     intel,cmd-data = <0x1B 0xD5>;
		     intel,cmd-lp = <1>;
		 };
	    ili7807b_cmd281 {
		     intel,cmd-type = <0x15>;
		     intel,cmd-data = <0x1C 0x02>;
		     intel,cmd-lp = <1>;
		 };
	    ili7807b_cmd282 {
		     intel,cmd-type = <0x15>;
		     intel,cmd-data = <0x1D 0x12>;
		     intel,cmd-lp = <1>;
		 };
	    ili7807b_cmd283 {
		     intel,cmd-type = <0x15>;
		     intel,cmd-data = <0x1E 0x02>;
		     intel,cmd-lp = <1>;
		 };
	    ili7807b_cmd284 {
		     intel,cmd-type = <0x15>;
		     intel,cmd-data = <0x1F 0x14>;
		     intel,cmd-lp = <1>;
		 };
	    ili7807b_cmd285 {
		     intel,cmd-type = <0x15>;
		     intel,cmd-data = <0x20 0x02>;
		     intel,cmd-lp = <1>;
		 };
	    ili7807b_cmd286 {
		     intel,cmd-type = <0x15>;
		     intel,cmd-data = <0x21 0x4A>;
		     intel,cmd-lp = <1>;
		 };
	    ili7807b_cmd287 {
		     intel,cmd-type = <0x15>;
		     intel,cmd-data = <0x22 0x02>;
		     intel,cmd-lp = <1>;
		 };
	    ili7807b_cmd288 {
		     intel,cmd-type = <0x15>;
		     intel,cmd-data = <0x23 0x85>;
		     intel,cmd-lp = <1>;
		 };
	    ili7807b_cmd289 {
		     intel,cmd-type = <0x15>;
		     intel,cmd-data = <0x24 0x02>;
		     intel,cmd-lp = <1>;
		 };
	    ili7807b_cmd290 {
		     intel,cmd-type = <0x15>;
		     intel,cmd-data = <0x25 0xAB>;
		     intel,cmd-lp = <1>;
		 };
	    ili7807b_cmd291 {
		     intel,cmd-type = <0x15>;
		     intel,cmd-data = <0x26 0x02>;
		     intel,cmd-lp = <1>;
		 };
	    ili7807b_cmd292 {
		     intel,cmd-type = <0x15>;
		     intel,cmd-data = <0x27 0xE0>;
		     intel,cmd-lp = <1>;
		 };
	    ili7807b_cmd293 {
		     intel,cmd-type = <0x15>;
		     intel,cmd-data = <0x28 0x03>;
		     intel,cmd-lp = <1>;
		 };
	    ili7807b_cmd294 {
		     intel,cmd-type = <0x15>;
		     intel,cmd-data = <0x29 0x03>;
		     intel,cmd-lp = <1>;
		 };
	    ili7807b_cmd295 {
		     intel,cmd-type = <0x15>;
		     intel,cmd-data = <0x2A 0x03>;
		     intel,cmd-lp = <1>;
		 };
	    ili7807b_cmd296 {
		     intel,cmd-type = <0x15>;
		     intel,cmd-data = <0x2B 0x2F>;
		     intel,cmd-lp = <1>;
		 };
	    ili7807b_cmd297 {
		     intel,cmd-type = <0x15>;
		     intel,cmd-data = <0x2C 0x03>;
		     intel,cmd-lp = <1>;
		 };
	    ili7807b_cmd298 {
		     intel,cmd-type = <0x15>;
		     intel,cmd-data = <0x2D 0x3D>;
		     intel,cmd-lp = <1>;
		 };
	    ili7807b_cmd299 {
		     intel,cmd-type = <0x15>;
		     intel,cmd-data = <0x2E 0x03>;
		     intel,cmd-lp = <1>;
		 };
	    ili7807b_cmd300 {
		     intel,cmd-type = <0x15>;
		     intel,cmd-data = <0x2F 0x4C>;
		     intel,cmd-lp = <1>;
		 };
	    ili7807b_cmd301 {
		     intel,cmd-type = <0x15>;
		     intel,cmd-data = <0x30 0x03>;
		     intel,cmd-lp = <1>;
		 };
	    ili7807b_cmd302 {
		     intel,cmd-type = <0x15>;
		     intel,cmd-data = <0x31 0x5C>;
		     intel,cmd-lp = <1>;
		 };
	    ili7807b_cmd303 {
		     intel,cmd-type = <0x15>;
		     intel,cmd-data = <0x32 0x03>;
		     intel,cmd-lp = <1>;
		 };
	    ili7807b_cmd304 {
		     intel,cmd-type = <0x15>;
		     intel,cmd-data = <0x33 0x6F>;
		     intel,cmd-lp = <1>;
		 };
	    ili7807b_cmd305 {
		     intel,cmd-type = <0x15>;
		     intel,cmd-data = <0x34 0x03>;
		     intel,cmd-lp = <1>;
		 };
	    ili7807b_cmd306 {
		     intel,cmd-type = <0x15>;
		     intel,cmd-data = <0x35 0x83>;
		     intel,cmd-lp = <1>;
		 };
	    ili7807b_cmd307 {
		     intel,cmd-type = <0x15>;
		     intel,cmd-data = <0x36 0x03>;
		     intel,cmd-lp = <1>;
		 };
	    ili7807b_cmd308 {
		     intel,cmd-type = <0x15>;
		     intel,cmd-data = <0x37 0x9C>;
		     intel,cmd-lp = <1>;
		 };
	    ili7807b_cmd309 {
		     intel,cmd-type = <0x15>;
		     intel,cmd-data = <0x38 0x03>;
		     intel,cmd-lp = <1>;
		 };
	    ili7807b_cmd310 {
		     intel,cmd-type = <0x15>;
		     intel,cmd-data = <0x39 0xBA>;
		     intel,cmd-lp = <1>;
		 };
	    ili7807b_cmd311 {
		     intel,cmd-type = <0x15>;
		     intel,cmd-data = <0x3A 0x03>;
		     intel,cmd-lp = <1>;
		 };
	    ili7807b_cmd312 {
		     intel,cmd-type = <0x15>;
		     intel,cmd-data = <0x3B 0xCE>;
		     intel,cmd-lp = <1>;
		 };
	    ili7807b_cmd313 {
		     intel,cmd-type = <0x15>;
		     intel,cmd-data = <0x3C 0x00>;
		     intel,cmd-lp = <1>;
		 };
	    ili7807b_cmd314 {
		     intel,cmd-type = <0x15>;
		     intel,cmd-data = <0x3D 0x29>;
		     intel,cmd-lp = <1>;
		 };
	    ili7807b_cmd315 {
		     intel,cmd-type = <0x15>;
		     intel,cmd-data = <0x3E 0x00>;
		     intel,cmd-lp = <1>;
		 };
	    ili7807b_cmd316 {
		     intel,cmd-type = <0x15>;
		     intel,cmd-data = <0x3F 0x2A>;
		     intel,cmd-lp = <1>;
		 };
	    ili7807b_cmd317 {
		     intel,cmd-type = <0x15>;
		     intel,cmd-data = <0x40 0x00>;
		     intel,cmd-lp = <1>;
		 };
	    ili7807b_cmd318 {
		     intel,cmd-type = <0x15>;
		     intel,cmd-data = <0x41 0x4B>;
		     intel,cmd-lp = <1>;
		 };
	    ili7807b_cmd319 {
		     intel,cmd-type = <0x15>;
		     intel,cmd-data = <0x42 0x00>;
		     intel,cmd-lp = <1>;
		 };
	    ili7807b_cmd320 {
		     intel,cmd-type = <0x15>;
		     intel,cmd-data = <0x43 0x63>;
		     intel,cmd-lp = <1>;
		 };
	    ili7807b_cmd321 {
		     intel,cmd-type = <0x15>;
		     intel,cmd-data = <0x44 0x00>;
		     intel,cmd-lp = <1>;
		 };
	    ili7807b_cmd322 {
		     intel,cmd-type = <0x15>;
		     intel,cmd-data = <0x45 0x79>;
		     intel,cmd-lp = <1>;
		 };
	    ili7807b_cmd323 {
		     intel,cmd-type = <0x15>;
		     intel,cmd-data = <0x46 0x00>;
		     intel,cmd-lp = <1>;
		 };
	    ili7807b_cmd324 {
		     intel,cmd-type = <0x15>;
		     intel,cmd-data = <0x47 0x8D>;
		     intel,cmd-lp = <1>;
		 };
	    ili7807b_cmd325 {
		     intel,cmd-type = <0x15>;
		     intel,cmd-data = <0x48 0x00>;
		     intel,cmd-lp = <1>;
		 };
	    ili7807b_cmd326 {
		     intel,cmd-type = <0x15>;
		     intel,cmd-data = <0x49 0x9E>;
		     intel,cmd-lp = <1>;
		 };
	    ili7807b_cmd327 {
		     intel,cmd-type = <0x15>;
		     intel,cmd-data = <0x4A 0x00>;
		     intel,cmd-lp = <1>;
		 };
	    ili7807b_cmd328 {
		     intel,cmd-type = <0x15>;
		     intel,cmd-data = <0x4B 0xAD>;
		     intel,cmd-lp = <1>;
		 };
	    ili7807b_cmd329 {
		     intel,cmd-type = <0x15>;
		     intel,cmd-data = <0x4C 0x00>;
		     intel,cmd-lp = <1>;
		 };
	    ili7807b_cmd330 {
		     intel,cmd-type = <0x15>;
		     intel,cmd-data = <0x4D 0xBB>;
		     intel,cmd-lp = <1>;
		 };
	    ili7807b_cmd331 {
		     intel,cmd-type = <0x15>;
		     intel,cmd-data = <0x4E 0x00>;
		     intel,cmd-lp = <1>;
		 };
	    ili7807b_cmd332 {
		     intel,cmd-type = <0x15>;
		     intel,cmd-data = <0x4F 0xEC>;
		     intel,cmd-lp = <1>;
		 };
	    ili7807b_cmd333 {
		     intel,cmd-type = <0x15>;
		     intel,cmd-data = <0x50 0x01>;
		     intel,cmd-lp = <1>;
		 };
	    ili7807b_cmd334 {
		     intel,cmd-type = <0x15>;
		     intel,cmd-data = <0x51 0x14>;
		     intel,cmd-lp = <1>;
		 };
	    ili7807b_cmd335 {
		     intel,cmd-type = <0x15>;
		     intel,cmd-data = <0x52 0x01>;
		     intel,cmd-lp = <1>;
		 };
	    ili7807b_cmd336 {
		     intel,cmd-type = <0x15>;
		     intel,cmd-data = <0x53 0x54>;
		     intel,cmd-lp = <1>;
		 };
	    ili7807b_cmd337 {
		     intel,cmd-type = <0x15>;
		     intel,cmd-data = <0x54 0x01>;
		     intel,cmd-lp = <1>;
		 };
	    ili7807b_cmd338 {
		     intel,cmd-type = <0x15>;
		     intel,cmd-data = <0x55 0x86>;
		     intel,cmd-lp = <1>;
		 };
	    ili7807b_cmd339 {
		     intel,cmd-type = <0x15>;
		     intel,cmd-data = <0x56 0x01>;
		     intel,cmd-lp = <1>;
		 };
	    ili7807b_cmd340 {
		     intel,cmd-type = <0x15>;
		     intel,cmd-data = <0x57 0xD5>;
		     intel,cmd-lp = <1>;
		 };
	    ili7807b_cmd341 {
		     intel,cmd-type = <0x15>;
		     intel,cmd-data = <0x58 0x02>;
		     intel,cmd-lp = <1>;
		 };
	    ili7807b_cmd342 {
		     intel,cmd-type = <0x15>;
		     intel,cmd-data = <0x59 0x12>;
		     intel,cmd-lp = <1>;
		 };
	    ili7807b_cmd343 {
		     intel,cmd-type = <0x15>;
		     intel,cmd-data = <0x5A 0x02>;
		     intel,cmd-lp = <1>;
		 };
	    ili7807b_cmd344 {
		     intel,cmd-type = <0x15>;
		     intel,cmd-data = <0x5B 0x14>;
		     intel,cmd-lp = <1>;
		 };
	    ili7807b_cmd345 {
		     intel,cmd-type = <0x15>;
		     intel,cmd-data = <0x5C 0x02>;
		     intel,cmd-lp = <1>;
		 };
	    ili7807b_cmd346 {
		     intel,cmd-type = <0x15>;
		     intel,cmd-data = <0x5D 0x4A>;
		     intel,cmd-lp = <1>;
		 };
	    ili7807b_cmd347 {
		     intel,cmd-type = <0x15>;
		     intel,cmd-data = <0x5E 0x02>;
		     intel,cmd-lp = <1>;
		 };
	    ili7807b_cmd348 {
		     intel,cmd-type = <0x15>;
		     intel,cmd-data = <0x5F 0x85>;
		     intel,cmd-lp = <1>;
		 };
	    ili7807b_cmd349 {
		     intel,cmd-type = <0x15>;
		     intel,cmd-data = <0x60 0x02>;
		     intel,cmd-lp = <1>;
		 };
	    ili7807b_cmd350 {
		     intel,cmd-type = <0x15>;
		     intel,cmd-data = <0x61 0xAB>;
		     intel,cmd-lp = <1>;
		 };
	    ili7807b_cmd351 {
		     intel,cmd-type = <0x15>;
		     intel,cmd-data = <0x62 0x02>;
		     intel,cmd-lp = <1>;
		 };
	    ili7807b_cmd352 {
		     intel,cmd-type = <0x15>;
		     intel,cmd-data = <0x63 0xE0>;
		     intel,cmd-lp = <1>;
		 };
	    ili7807b_cmd353 {
		     intel,cmd-type = <0x15>;
		     intel,cmd-data = <0x64 0x03>;
		     intel,cmd-lp = <1>;
		 };
	    ili7807b_cmd354 {
		     intel,cmd-type = <0x15>;
		     intel,cmd-data = <0x65 0x03>;
		     intel,cmd-lp = <1>;
		 };
	    ili7807b_cmd355 {
		     intel,cmd-type = <0x15>;
		     intel,cmd-data = <0x66 0x03>;
		     intel,cmd-lp = <1>;
		 };
	    ili7807b_cmd356 {
		     intel,cmd-type = <0x15>;
		     intel,cmd-data = <0x67 0x2F>;
		     intel,cmd-lp = <1>;
		 };
	    ili7807b_cmd357 {
		     intel,cmd-type = <0x15>;
		     intel,cmd-data = <0x68 0x03>;
		     intel,cmd-lp = <1>;
		 };
	    ili7807b_cmd358 {
		     intel,cmd-type = <0x15>;
		     intel,cmd-data = <0x69 0x3D>;
		     intel,cmd-lp = <1>;
		 };
	    ili7807b_cmd359 {
		     intel,cmd-type = <0x15>;
		     intel,cmd-data = <0x6A 0x03>;
		     intel,cmd-lp = <1>;
		 };
	    ili7807b_cmd360 {
		     intel,cmd-type = <0x15>;
		     intel,cmd-data = <0x6B 0x4C>;
		     intel,cmd-lp = <1>;
		 };
	    ili7807b_cmd361 {
		     intel,cmd-type = <0x15>;
		     intel,cmd-data = <0x6C 0x03>;
		     intel,cmd-lp = <1>;
		 };
	    ili7807b_cmd362 {
		     intel,cmd-type = <0x15>;
		     intel,cmd-data = <0x6D 0x5C>;
		     intel,cmd-lp = <1>;
		 };
	    ili7807b_cmd363 {
		     intel,cmd-type = <0x15>;
		     intel,cmd-data = <0x6E 0x03>;
		     intel,cmd-lp = <1>;
		 };
	    ili7807b_cmd364 {
		     intel,cmd-type = <0x15>;
		     intel,cmd-data = <0x6F 0x6F>;
		     intel,cmd-lp = <1>;
		 };
	    ili7807b_cmd365 {
		     intel,cmd-type = <0x15>;
		     intel,cmd-data = <0x70 0x03>;
		     intel,cmd-lp = <1>;
		 };
	    ili7807b_cmd366 {
		     intel,cmd-type = <0x15>;
		     intel,cmd-data = <0x71 0x83>;
		     intel,cmd-lp = <1>;
		 };
	    ili7807b_cmd367 {
		     intel,cmd-type = <0x15>;
		     intel,cmd-data = <0x72 0x03>;
		     intel,cmd-lp = <1>;
		 };
	    ili7807b_cmd368 {
		     intel,cmd-type = <0x15>;
		     intel,cmd-data = <0x73 0x9C>;
		     intel,cmd-lp = <1>;
		 };
	    ili7807b_cmd369 {
		     intel,cmd-type = <0x15>;
		     intel,cmd-data = <0x74 0x03>;
		     intel,cmd-lp = <1>;
		 };
	    ili7807b_cmd370 {
		     intel,cmd-type = <0x15>;
		     intel,cmd-data = <0x75 0xBA>;
		     intel,cmd-lp = <1>;
		 };
	    ili7807b_cmd371 {
		     intel,cmd-type = <0x15>;
		     intel,cmd-data = <0x76 0x03>;
		     intel,cmd-lp = <1>;
		 };
	    ili7807b_cmd372 {
		     intel,cmd-type = <0x15>;
		     intel,cmd-data = <0x77 0xCE>;
		     intel,cmd-lp = <1>;
		 };
	    ili7807b_cmd373 {
		     intel,cmd-type = <0x15>;
		     intel,cmd-data = <0x78 0x01>;
		     intel,cmd-lp = <1>;
		 };
	    ili7807b_cmd374 {
		     intel,cmd-type = <0x15>;
		     intel,cmd-data = <0x79 0x01>;
		     intel,cmd-lp = <1>;
		 };
	    ili7807b_cmd375 {
		     intel,cmd-type = <0x39>;
		     intel,cmd-data = <0xFF 0x78 0x07 0x04>;
		     intel,cmd-lp = <1>;
		 };
	    ili7807b_cmd376 {
		     intel,cmd-type = <0x15>;
		     intel,cmd-data = <0x00 0x00>;
		     intel,cmd-lp = <1>;
		 };
	    ili7807b_cmd377 {
		     intel,cmd-type = <0x15>;
		     intel,cmd-data = <0x01 0x1B>;
		     intel,cmd-lp = <1>;
		 };
	    ili7807b_cmd378 {
		     intel,cmd-type = <0x15>;
		     intel,cmd-data = <0x02 0x00>;
		     intel,cmd-lp = <1>;
		 };
	    ili7807b_cmd379 {
		     intel,cmd-type = <0x15>;
		     intel,cmd-data = <0x03 0x2C>;
		     intel,cmd-lp = <1>;
		 };
	    ili7807b_cmd380 {
		     intel,cmd-type = <0x15>;
		     intel,cmd-data = <0x04 0x00>;
		     intel,cmd-lp = <1>;
		 };
	    ili7807b_cmd381 {
		     intel,cmd-type = <0x15>;
		     intel,cmd-data = <0x05 0x4C>;
		     intel,cmd-lp = <1>;
		 };
	    ili7807b_cmd382 {
		     intel,cmd-type = <0x15>;
		     intel,cmd-data = <0x06 0x00>;
		     intel,cmd-lp = <1>;
		 };
	    ili7807b_cmd383 {
		     intel,cmd-type = <0x15>;
		     intel,cmd-data = <0x07 0x64>;
		     intel,cmd-lp = <1>;
		 };
	    ili7807b_cmd384 {
		     intel,cmd-type = <0x15>;
		     intel,cmd-data = <0x08 0x00>;
		     intel,cmd-lp = <1>;
		 };
	    ili7807b_cmd385 {
		     intel,cmd-type = <0x15>;
		     intel,cmd-data = <0x09 0x7A>;
		     intel,cmd-lp = <1>;
		 };
	    ili7807b_cmd386 {
		     intel,cmd-type = <0x15>;
		     intel,cmd-data = <0x0A 0x00>;
		     intel,cmd-lp = <1>;
		 };
	    ili7807b_cmd387 {
		     intel,cmd-type = <0x15>;
		     intel,cmd-data = <0x0B 0x8D>;
		     intel,cmd-lp = <1>;
		 };
	    ili7807b_cmd388 {
		     intel,cmd-type = <0x15>;
		     intel,cmd-data = <0x0C 0x00>;
		     intel,cmd-lp = <1>;
		 };
	    ili7807b_cmd389 {
		     intel,cmd-type = <0x15>;
		     intel,cmd-data = <0x0D 0x9E>;
		     intel,cmd-lp = <1>;
		 };
	    ili7807b_cmd390 {
		     intel,cmd-type = <0x15>;
		     intel,cmd-data = <0x0E 0x00>;
		     intel,cmd-lp = <1>;
		 };
	    ili7807b_cmd391 {
		     intel,cmd-type = <0x15>;
		     intel,cmd-data = <0x0F 0xAD>;
		     intel,cmd-lp = <1>;
		 };
	    ili7807b_cmd392 {
		     intel,cmd-type = <0x15>;
		     intel,cmd-data = <0x10 0x00>;
		     intel,cmd-lp = <1>;
		 };
	    ili7807b_cmd393 {
		     intel,cmd-type = <0x15>;
		     intel,cmd-data = <0x11 0xBB>;
		     intel,cmd-lp = <1>;
		 };
	    ili7807b_cmd394 {
		     intel,cmd-type = <0x15>;
		     intel,cmd-data = <0x12 0x00>;
		     intel,cmd-lp = <1>;
		 };
	    ili7807b_cmd395 {
		     intel,cmd-type = <0x15>;
		     intel,cmd-data = <0x13 0xEC>;
		     intel,cmd-lp = <1>;
		 };
	    ili7807b_cmd396 {
		     intel,cmd-type = <0x15>;
		     intel,cmd-data = <0x14 0x01>;
		     intel,cmd-lp = <1>;
		 };
	    ili7807b_cmd397 {
		     intel,cmd-type = <0x15>;
		     intel,cmd-data = <0x15 0x14>;
		     intel,cmd-lp = <1>;
		 };
	    ili7807b_cmd398 {
		     intel,cmd-type = <0x15>;
		     intel,cmd-data = <0x16 0x01>;
		     intel,cmd-lp = <1>;
		 };
	    ili7807b_cmd399 {
		     intel,cmd-type = <0x15>;
		     intel,cmd-data = <0x17 0x54>;
		     intel,cmd-lp = <1>;
		 };
	    ili7807b_cmd400 {
		     intel,cmd-type = <0x15>;
		     intel,cmd-data = <0x18 0x01>;
		     intel,cmd-lp = <1>;
		 };
	    ili7807b_cmd401 {
		     intel,cmd-type = <0x15>;
		     intel,cmd-data = <0x19 0x87>;
		     intel,cmd-lp = <1>;
		 };
	    ili7807b_cmd402 {
		     intel,cmd-type = <0x15>;
		     intel,cmd-data = <0x1A 0x01>;
		     intel,cmd-lp = <1>;
		 };
	    ili7807b_cmd403 {
		     intel,cmd-type = <0x15>;
		     intel,cmd-data = <0x1B 0xD5>;
		     intel,cmd-lp = <1>;
		 };
	    ili7807b_cmd404 {
		     intel,cmd-type = <0x15>;
		     intel,cmd-data = <0x1C 0x02>;
		     intel,cmd-lp = <1>;
		 };
	    ili7807b_cmd405 {
		     intel,cmd-type = <0x15>;
		     intel,cmd-data = <0x1D 0x13>;
		     intel,cmd-lp = <1>;
		 };
	    ili7807b_cmd406 {
		     intel,cmd-type = <0x15>;
		     intel,cmd-data = <0x1E 0x02>;
		     intel,cmd-lp = <1>;
		 };
	    ili7807b_cmd407 {
		     intel,cmd-type = <0x15>;
		     intel,cmd-data = <0x1F 0x15>;
		     intel,cmd-lp = <1>;
		 };
	    ili7807b_cmd408 {
		     intel,cmd-type = <0x15>;
		     intel,cmd-data = <0x20 0x02>;
		     intel,cmd-lp = <1>;
		 };
	    ili7807b_cmd409 {
		     intel,cmd-type = <0x15>;
		     intel,cmd-data = <0x21 0x4C>;
		     intel,cmd-lp = <1>;
		 };
	    ili7807b_cmd410 {
		     intel,cmd-type = <0x15>;
		     intel,cmd-data = <0x22 0x02>;
		     intel,cmd-lp = <1>;
		 };
	    ili7807b_cmd411 {
		     intel,cmd-type = <0x15>;
		     intel,cmd-data = <0x23 0x86>;
		     intel,cmd-lp = <1>;
		 };
	    ili7807b_cmd412 {
		     intel,cmd-type = <0x15>;
		     intel,cmd-data = <0x24 0x02>;
		     intel,cmd-lp = <1>;
		 };
	    ili7807b_cmd413 {
		     intel,cmd-type = <0x15>;
		     intel,cmd-data = <0x25 0xAC>;
		     intel,cmd-lp = <1>;
		 };
	    ili7807b_cmd414 {
		     intel,cmd-type = <0x15>;
		     intel,cmd-data = <0x26 0x02>;
		     intel,cmd-lp = <1>;
		 };
	    ili7807b_cmd415 {
		     intel,cmd-type = <0x15>;
		     intel,cmd-data = <0x27 0xE2>;
		     intel,cmd-lp = <1>;
		 };
	    ili7807b_cmd416 {
		     intel,cmd-type = <0x15>;
		     intel,cmd-data = <0x28 0x03>;
		     intel,cmd-lp = <1>;
		 };
	    ili7807b_cmd417 {
		     intel,cmd-type = <0x15>;
		     intel,cmd-data = <0x29 0x09>;
		     intel,cmd-lp = <1>;
		 };
	    ili7807b_cmd418 {
		     intel,cmd-type = <0x15>;
		     intel,cmd-data = <0x2A 0x03>;
		     intel,cmd-lp = <1>;
		 };
	    ili7807b_cmd419 {
		     intel,cmd-type = <0x15>;
		     intel,cmd-data = <0x2B 0x46>;
		     intel,cmd-lp = <1>;
		 };
	    ili7807b_cmd420 {
		     intel,cmd-type = <0x15>;
		     intel,cmd-data = <0x2C 0x03>;
		     intel,cmd-lp = <1>;
		 };
	    ili7807b_cmd421 {
		     intel,cmd-type = <0x15>;
		     intel,cmd-data = <0x2D 0x52>;
		     intel,cmd-lp = <1>;
		 };
	    ili7807b_cmd422 {
		     intel,cmd-type = <0x15>;
		     intel,cmd-data = <0x2E 0x03>;
		     intel,cmd-lp = <1>;
		 };
	    ili7807b_cmd423 {
		     intel,cmd-type = <0x15>;
		     intel,cmd-data = <0x2F 0x5E>;
		     intel,cmd-lp = <1>;
		 };
	    ili7807b_cmd424 {
		     intel,cmd-type = <0x15>;
		     intel,cmd-data = <0x30 0x03>;
		     intel,cmd-lp = <1>;
		 };
	    ili7807b_cmd425 {
		     intel,cmd-type = <0x15>;
		     intel,cmd-data = <0x31 0x6C>;
		     intel,cmd-lp = <1>;
		 };
	    ili7807b_cmd426 {
		     intel,cmd-type = <0x15>;
		     intel,cmd-data = <0x32 0x03>;
		     intel,cmd-lp = <1>;
		 };
	    ili7807b_cmd427 {
		     intel,cmd-type = <0x15>;
		     intel,cmd-data = <0x33 0x7B>;
		     intel,cmd-lp = <1>;
		 };
	    ili7807b_cmd428 {
		     intel,cmd-type = <0x15>;
		     intel,cmd-data = <0x34 0x03>;
		     intel,cmd-lp = <1>;
		 };
	    ili7807b_cmd429 {
		     intel,cmd-type = <0x15>;
		     intel,cmd-data = <0x35 0x8D>;
		     intel,cmd-lp = <1>;
		 };
	    ili7807b_cmd430 {
		     intel,cmd-type = <0x15>;
		     intel,cmd-data = <0x36 0x03>;
		     intel,cmd-lp = <1>;
		 };
	    ili7807b_cmd431 {
		     intel,cmd-type = <0x15>;
		     intel,cmd-data = <0x37 0x9F>;
		     intel,cmd-lp = <1>;
		 };
	    ili7807b_cmd432 {
		     intel,cmd-type = <0x15>;
		     intel,cmd-data = <0x38 0x03>;
		     intel,cmd-lp = <1>;
		 };
	    ili7807b_cmd433 {
		     intel,cmd-type = <0x15>;
		     intel,cmd-data = <0x39 0xB3>;
		     intel,cmd-lp = <1>;
		 };
	    ili7807b_cmd434 {
		     intel,cmd-type = <0x15>;
		     intel,cmd-data = <0x3A 0x03>;
		     intel,cmd-lp = <1>;
		 };
	    ili7807b_cmd435 {
		     intel,cmd-type = <0x15>;
		     intel,cmd-data = <0x3B 0xCE>;
		     intel,cmd-lp = <1>;
		 };
	    ili7807b_cmd436 {
		     intel,cmd-type = <0x15>;
		     intel,cmd-data = <0x3C 0x00>;
		     intel,cmd-lp = <1>;
		 };
	    ili7807b_cmd437 {
		     intel,cmd-type = <0x15>;
		     intel,cmd-data = <0x3D 0x1B>;
		     intel,cmd-lp = <1>;
		 };
	    ili7807b_cmd438 {
		     intel,cmd-type = <0x15>;
		     intel,cmd-data = <0x3E 0x00>;
		     intel,cmd-lp = <1>;
		 };
	    ili7807b_cmd439 {
		     intel,cmd-type = <0x15>;
		     intel,cmd-data = <0x3F 0x2C>;
		     intel,cmd-lp = <1>;
		 };
	    ili7807b_cmd440 {
		     intel,cmd-type = <0x15>;
		     intel,cmd-data = <0x40 0x00>;
		     intel,cmd-lp = <1>;
		 };
	    ili7807b_cmd441 {
		     intel,cmd-type = <0x15>;
		     intel,cmd-data = <0x41 0x4C>;
		     intel,cmd-lp = <1>;
		 };
	    ili7807b_cmd442 {
		     intel,cmd-type = <0x15>;
		     intel,cmd-data = <0x42 0x00>;
		     intel,cmd-lp = <1>;
		 };
	    ili7807b_cmd443 {
		     intel,cmd-type = <0x15>;
		     intel,cmd-data = <0x43 0x64>;
		     intel,cmd-lp = <1>;
		 };
	    ili7807b_cmd444 {
		     intel,cmd-type = <0x15>;
		     intel,cmd-data = <0x44 0x00>;
		     intel,cmd-lp = <1>;
		 };
	    ili7807b_cmd445 {
		     intel,cmd-type = <0x15>;
		     intel,cmd-data = <0x45 0x7A>;
		     intel,cmd-lp = <1>;
		 };
	    ili7807b_cmd446 {
		     intel,cmd-type = <0x15>;
		     intel,cmd-data = <0x46 0x00>;
		     intel,cmd-lp = <1>;
		 };
	    ili7807b_cmd447 {
		     intel,cmd-type = <0x15>;
		     intel,cmd-data = <0x47 0x8D>;
		     intel,cmd-lp = <1>;
		 };
	    ili7807b_cmd448 {
		     intel,cmd-type = <0x15>;
		     intel,cmd-data = <0x48 0x00>;
		     intel,cmd-lp = <1>;
		 };
	    ili7807b_cmd449 {
		     intel,cmd-type = <0x15>;
		     intel,cmd-data = <0x49 0x9E>;
		     intel,cmd-lp = <1>;
		 };
	    ili7807b_cmd450 {
		     intel,cmd-type = <0x15>;
		     intel,cmd-data = <0x4A 0x00>;
		     intel,cmd-lp = <1>;
		 };
	    ili7807b_cmd451 {
		     intel,cmd-type = <0x15>;
		     intel,cmd-data = <0x4B 0xAD>;
		     intel,cmd-lp = <1>;
		 };
	    ili7807b_cmd452 {
		     intel,cmd-type = <0x15>;
		     intel,cmd-data = <0x4C 0x00>;
		     intel,cmd-lp = <1>;
		 };
	    ili7807b_cmd453 {
		     intel,cmd-type = <0x15>;
		     intel,cmd-data = <0x4D 0xBB>;
		     intel,cmd-lp = <1>;
		 };
	    ili7807b_cmd454 {
		     intel,cmd-type = <0x15>;
		     intel,cmd-data = <0x4E 0x00>;
		     intel,cmd-lp = <1>;
		 };
	    ili7807b_cmd455 {
		     intel,cmd-type = <0x15>;
		     intel,cmd-data = <0x4F 0xEC>;
		     intel,cmd-lp = <1>;
		 };
	    ili7807b_cmd456 {
		     intel,cmd-type = <0x15>;
		     intel,cmd-data = <0x50 0x01>;
		     intel,cmd-lp = <1>;
		 };
	    ili7807b_cmd457 {
		     intel,cmd-type = <0x15>;
		     intel,cmd-data = <0x51 0x14>;
		     intel,cmd-lp = <1>;
		 };
	    ili7807b_cmd458 {
		     intel,cmd-type = <0x15>;
		     intel,cmd-data = <0x52 0x01>;
		     intel,cmd-lp = <1>;
		 };
	    ili7807b_cmd459 {
		     intel,cmd-type = <0x15>;
		     intel,cmd-data = <0x53 0x54>;
		     intel,cmd-lp = <1>;
		 };
	    ili7807b_cmd460 {
		     intel,cmd-type = <0x15>;
		     intel,cmd-data = <0x54 0x01>;
		     intel,cmd-lp = <1>;
		 };
	    ili7807b_cmd461 {
		     intel,cmd-type = <0x15>;
		     intel,cmd-data = <0x55 0x87>;
		     intel,cmd-lp = <1>;
		 };
	    ili7807b_cmd462 {
		     intel,cmd-type = <0x15>;
		     intel,cmd-data = <0x56 0x01>;
		     intel,cmd-lp = <1>;
		 };
	    ili7807b_cmd463 {
		     intel,cmd-type = <0x15>;
		     intel,cmd-data = <0x57 0xD5>;
		     intel,cmd-lp = <1>;
		 };
	    ili7807b_cmd464 {
		     intel,cmd-type = <0x15>;
		     intel,cmd-data = <0x58 0x02>;
		     intel,cmd-lp = <1>;
		 };
	    ili7807b_cmd465 {
		     intel,cmd-type = <0x15>;
		     intel,cmd-data = <0x59 0x13>;
		     intel,cmd-lp = <1>;
		 };
	    ili7807b_cmd466 {
		     intel,cmd-type = <0x15>;
		     intel,cmd-data = <0x5A 0x02>;
		     intel,cmd-lp = <1>;
		 };
	    ili7807b_cmd467 {
		     intel,cmd-type = <0x15>;
		     intel,cmd-data = <0x5B 0x15>;
		     intel,cmd-lp = <1>;
		 };
	    ili7807b_cmd468 {
		     intel,cmd-type = <0x15>;
		     intel,cmd-data = <0x5C 0x02>;
		     intel,cmd-lp = <1>;
		 };
	    ili7807b_cmd469 {
		     intel,cmd-type = <0x15>;
		     intel,cmd-data = <0x5D 0x4C>;
		     intel,cmd-lp = <1>;
		 };
	    ili7807b_cmd470 {
		     intel,cmd-type = <0x15>;
		     intel,cmd-data = <0x5E 0x02>;
		     intel,cmd-lp = <1>;
		 };
	    ili7807b_cmd471 {
		     intel,cmd-type = <0x15>;
		     intel,cmd-data = <0x5F 0x86>;
		     intel,cmd-lp = <1>;
		 };
	    ili7807b_cmd472 {
		     intel,cmd-type = <0x15>;
		     intel,cmd-data = <0x60 0x02>;
		     intel,cmd-lp = <1>;
		 };
	    ili7807b_cmd473 {
		     intel,cmd-type = <0x15>;
		     intel,cmd-data = <0x61 0xAC>;
		     intel,cmd-lp = <1>;
		 };
	    ili7807b_cmd474 {
		     intel,cmd-type = <0x15>;
		     intel,cmd-data = <0x62 0x02>;
		     intel,cmd-lp = <1>;
		 };
	    ili7807b_cmd475 {
		     intel,cmd-type = <0x15>;
		     intel,cmd-data = <0x63 0xE2>;
		     intel,cmd-lp = <1>;
		 };
	    ili7807b_cmd476 {
		     intel,cmd-type = <0x15>;
		     intel,cmd-data = <0x64 0x03>;
		     intel,cmd-lp = <1>;
		 };
	    ili7807b_cmd477 {
		     intel,cmd-type = <0x15>;
		     intel,cmd-data = <0x65 0x09>;
		     intel,cmd-lp = <1>;
		 };
	    ili7807b_cmd478 {
		     intel,cmd-type = <0x15>;
		     intel,cmd-data = <0x66 0x03>;
		     intel,cmd-lp = <1>;
		 };
	    ili7807b_cmd479 {
		     intel,cmd-type = <0x15>;
		     intel,cmd-data = <0x67 0x46>;
		     intel,cmd-lp = <1>;
		 };
	    ili7807b_cmd480 {
		     intel,cmd-type = <0x15>;
		     intel,cmd-data = <0x68 0x03>;
		     intel,cmd-lp = <1>;
		 };
	    ili7807b_cmd481 {
		     intel,cmd-type = <0x15>;
		     intel,cmd-data = <0x69 0x52>;
		     intel,cmd-lp = <1>;
		 };
	    ili7807b_cmd482 {
		     intel,cmd-type = <0x15>;
		     intel,cmd-data = <0x6A 0x03>;
		     intel,cmd-lp = <1>;
		 };
	    ili7807b_cmd483 {
		     intel,cmd-type = <0x15>;
		     intel,cmd-data = <0x6B 0x5E>;
		     intel,cmd-lp = <1>;
		 };
	    ili7807b_cmd484 {
		     intel,cmd-type = <0x15>;
		     intel,cmd-data = <0x6C 0x03>;
		     intel,cmd-lp = <1>;
		 };
	    ili7807b_cmd485 {
		     intel,cmd-type = <0x15>;
		     intel,cmd-data = <0x6D 0x6C>;
		     intel,cmd-lp = <1>;
		 };
	    ili7807b_cmd486 {
		     intel,cmd-type = <0x15>;
		     intel,cmd-data = <0x6E 0x03>;
		     intel,cmd-lp = <1>;
		 };
	    ili7807b_cmd487 {
		     intel,cmd-type = <0x15>;
		     intel,cmd-data = <0x6F 0x7B>;
		     intel,cmd-lp = <1>;
		 };
	    ili7807b_cmd488 {
		     intel,cmd-type = <0x15>;
		     intel,cmd-data = <0x70 0x03>;
		     intel,cmd-lp = <1>;
		 };
	    ili7807b_cmd489 {
		     intel,cmd-type = <0x15>;
		     intel,cmd-data = <0x71 0x8D>;
		     intel,cmd-lp = <1>;
		 };
	    ili7807b_cmd490 {
		     intel,cmd-type = <0x15>;
		     intel,cmd-data = <0x72 0x03>;
		     intel,cmd-lp = <1>;
		 };
	    ili7807b_cmd491 {
		     intel,cmd-type = <0x15>;
		     intel,cmd-data = <0x73 0x9F>;
		     intel,cmd-lp = <1>;
		 };
	    ili7807b_cmd492 {
		     intel,cmd-type = <0x15>;
		     intel,cmd-data = <0x74 0x03>;
		     intel,cmd-lp = <1>;
		 };
	    ili7807b_cmd493 {
		     intel,cmd-type = <0x15>;
		     intel,cmd-data = <0x75 0xB3>;
		     intel,cmd-lp = <1>;
		 };
	    ili7807b_cmd494 {
		     intel,cmd-type = <0x15>;
		     intel,cmd-data = <0x76 0x03>;
		     intel,cmd-lp = <1>;
		 };
	    ili7807b_cmd495 {
		     intel,cmd-type = <0x15>;
		     intel,cmd-data = <0x77 0xCE>;
		     intel,cmd-lp = <1>;
		 };
	    ili7807b_cmd496 {
		     intel,cmd-type = <0x15>;
		     intel,cmd-data = <0x78 0x01>;
		     intel,cmd-lp = <1>;
		 };
	    ili7807b_cmd497 {
		     intel,cmd-type = <0x15>;
		     intel,cmd-data = <0x79 0x01>;
		     intel,cmd-lp = <1>;
		 };
	    ili7807b_cmd498 {
		     intel,cmd-type = <0x39>;
		     intel,cmd-data = <0xFF 0x78 0x07 0x00>;
		     intel,cmd-lp = <1>;
		 };
	    ili7807b_cmd499 {
		     intel,cmd-type = <0x15>;
		     intel,cmd-data = <0x35 0x00>;
		     intel,cmd-lp = <1>;
		 };
	    ili7807b_cmd500 {
		     intel,cmd-type = <0x15>;
		     intel,cmd-data = <0x11 0x00>;
		     intel,cmd-delay = <120>;
		     intel,cmd-lp = <1>;
		 };
	    ili7807b_cmd501 {
		     intel,cmd-type = <0x15>;
		     intel,cmd-data = <0x29 0x00>;
		     intel,cmd-lp = <1>;
		 };
	};

	gpio-power-on {
		power_en {
			intel,gpio-type = "vhigh";
			intel,gpio-value-delay = <1 41>;
		};
		reset1 {
			intel,gpio-type = "reset";
			intel,gpio-value-delay = <1 10>;
		};
		reset2 {
			intel,gpio-type = "reset";
			intel,gpio-value-delay = <0 10>;
		};
		reset3 {
			intel,gpio-type = "reset";
			intel,gpio-value-delay = <1 10>;
		};
	};

	gpio-power-off {
		reset {
			intel,gpio-type = "reset";
			intel,gpio-value-delay = <0 1>;
		};
		/*power_en {
		  intel,gpio-type = "vhigh";
		  intel,gpio-value-delay = <0 0>;
		  };*/
	};

	cmd-sleep-in {
		display-off {
			intel,cmd-type = <0x05>;
			intel,cmd-data = <0x28>;
			intel,cmd-delay = <120>;
			intel,cmd-lp = <1>;
		};
		sleep-in {
			intel,cmd-type = <0x05>;
			intel,cmd-data = <0x10>;
			intel,cmd-delay = <20>;
			intel,cmd-lp = <1>;
		};
	};

	cmd-sleep-out {
		sleep-out {
			intel,cmd-type = <0x05>;
			intel,cmd-data = <0x11>;
			intel,cmd-delay = <120>;
			intel,cmd-lp = <1>;
		};
		display-on {
			intel,cmd-type = <0x05>;
			intel,cmd-data = <0x29>;
			intel,cmd-delay = <20>;
			intel,cmd-lp = <1>;
		};
	};
};
